# S1C31D01 register map
Vendor: Epson; Series: S1C31D01; File version: 1.00
CPU: CM0PLUS r0p1, little endian, MPU, no FPU, VTOR, 2 interrupt priority bits
Registers are 16-bit, read-write, reset 0x0 unless marked. A register's access mark holds for its fields unless they carry their own. Offsets are from the block's base; [hi:lo] are bit positions.

## MDC — Memory display controller
Base 0x40003000
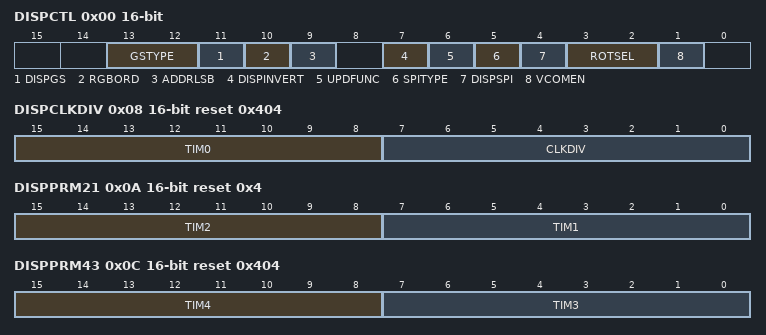
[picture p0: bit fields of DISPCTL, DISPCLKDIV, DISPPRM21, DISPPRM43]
0x00 DISPCTL — Display Control Register
  [13:12] GSTYPE — Select grayscale panel type
  [11] DISPGS — Select grayscale panel mode
  [10] RGBORD — This bit configures the order of the pixel data bits sent (LSB or MSB first) for Sharp panels.
    0=RGB (R is sent first); 1=BGR (G is sent first)
  [9] ADDRLSB — This bit configures the order of the Address bits sent (LSB or MSB first) for Sharp panels.
    0=MSB (MSB first); 1=LSB (LSB first)
  [7] DISPINVERT — This bit enables/disables inversion of pixels sent to the display.
    0=NORMAL (Normal (no inversion)); 1=INVERT (Pixel bits inverted)
  [6] UPDFUNC — This bit selects the function for Sharp or Epson display when frame update is triggered.
  [5] SPITYPE — This bit selects the type of Sharp panel.
  [4] DISPSPI — This bit selects the type of panel.
  [3:2] ROTSEL — This bit selects the rotation of the image from display RAM to the panel during a frame update.
    0=NOROT (No rotation (0 degrees)); 3=R270 (270-degree counterclockwise rotation); 2=R180 (180-degree counterclockwise rotation); 1=R90 (90-degree counterclockwise rotation)
  [1] VCOMEN — This bit enables or disables the VCOM and XFRP outputs. When enabled, the frequency of the VCOM /XFRP is determined by the MDC_DISPVCOMDIV register.
0x02 DISPWIDTH reset 0xB4 — Display Width Register
  [9:0] DISPWIDTH — Display width in pixels.
0x04 DISPHEIGHT reset 0xB4 — Display Height Register
  [9:0] DISPHEIGHT — Display height in pixels.
0x06 DISPVCOMDIV reset 0x222 — Display VCOM Clock Divider Register
  [15:0] DISPVCOMDIV — VCOM clock divider. VCOM/XFRP toggle period = [M*4*(VCOMCLKDIV + 1)],where M is the 32.768kHz clock period (1/32768).
0x08 DISPCLKDIV reset 0x404 — Display Clock Divider Register
  [15:8] TIM0
  [7:0] CLKDIV — Timing Parameter 0
0x0A DISPPRM21 reset 0x4 — Display Parameters 1 and 2 Register
  [15:8] TIM2 — Timing Parameter 2.
  [7:0] TIM1 — Timing Parameter 1.
0x0C DISPPRM43 reset 0x404 — Display Parameters 3 and 4 Register
  [15:8] TIM4 — Timing Parameter 4.
  [7:0] TIM3 — Timing Parameter 3.
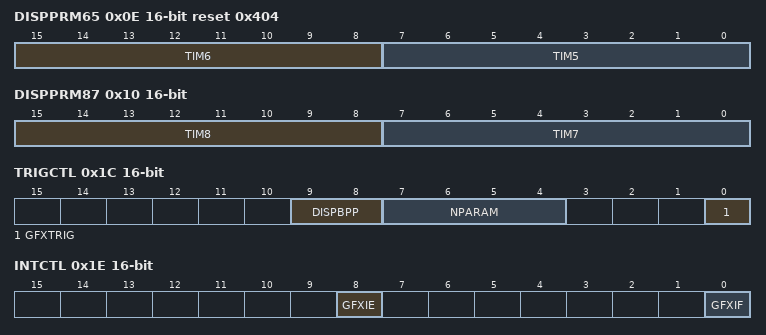
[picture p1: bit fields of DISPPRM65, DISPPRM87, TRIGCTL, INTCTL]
0x0E DISPPRM65 reset 0x404 — Display Parameters 5 and 6 Register
  [15:8] TIM6 — Timing Parameter 6.
  [7:0] TIM5 — Timing Parameter 5.
0x10 DISPPRM87 — Display Parameters 5 and 6 Register
  [15:8] TIM8 — Timing Parameter 8.
  [7:0] TIM7 — Timing Parameter 7.
0x12 DISPSTARTY — Display Update Start Line Register
  [9:0] STARTY — Starting line of image for display update
0x14 DISPENDY reset 0xB3 — Display Update End Line Register
  [9:0] ENDY — Ending line of image for display update.
0x16 DISPSTRIDE reset 0xB4 — MDC Display Frame Buffer Stride Register
  [9:0] DISPSTRIDE
0x18 DISPFRMBUF0 — Display Frame Buffer Base Address Register 0
  [15:0] FRMBUFFADDR — Bits 15-0 of the display frame buffer base address register.
0x1A DISPFRMBUF1 — Display Frame Buffer Base Address Register 1
  [15:0] FRMBUFFADDR — Bits 23-16 of the display frame buffer base address register.
0x1C TRIGCTL — Trigger Control Register
  [9:8] DISPBPP
  [7:4] NPARAM
  [0] GFXTRIG — This bit triggers the selected graphics acceleration function specified in GFXFUNC[2:0].
0x1E INTCTL — Interrupt Control Register
  [8] GFXIE — This bit enables/disables the graphics acceleration interrupt.
  [0] GFXIF — This bit is the graphics interrupt status flag.
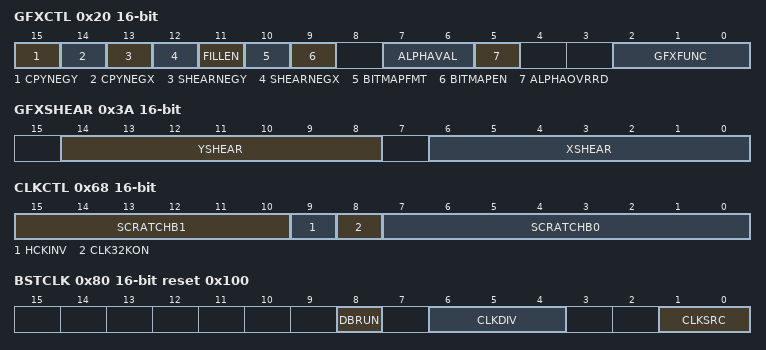
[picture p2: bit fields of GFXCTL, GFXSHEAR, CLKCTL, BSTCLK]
0x20 GFXCTL — Graphics Control Register
  [15] CPYNEGY — For the Copy functions, this bit selects whether or not the Y coordinate value of the input pixel should be negated (make negative) to create the effect of "flip around the X axis".
  [14] CPYNEGX — For the Copy functions, this bit selects whether or not the X coordinate value of the input pixel should be negated (make negative) to create the effect of "flip around the Y axis".
  [13] SHEARNEGY — For the Copy with shearing function, this bit selects whether or not the vertical shear value is negated (made negative).
  [12] SHEARNEGX — For the Copy with shearing function, this bit selects whether or not the horizontal shear value is negated (made negative).
  [11] FILLEN — This bit enables/disables fill option for drawing and copying functions.
  [10] BITMAPFMT — This bit selects 1-bit or 2-bit bitmap format for copying functions. See Section 0 for details.
  [9] BITMAPEN — This bit specifies whether the source for copying functions is an image or a bitmap.
  [7:6] ALPHAVAL — When alpha value override is enabled (ALPHAOVRRD=1), this specifies the override alpha value to use.
  [5] ALPHAOVRRD — This bit enables/disables alpha value override for copying functions.
  [2:0] GFXFUNC — These bits specify the graphics accelerator function to execute when the GFXTRIG bit in the MDC_TRIGCTL register is set to 1.
    0=CPOYROTSCALE (Image/bitmap copy with rotate and scale.); 1=COPYHVSHEAR (Image/bitmap copy with horizontal and vertical shear); 2=RECTDRAW (Rectangle (filled or unfilled) draw); 3=LINEDRAW (Line draw with thickness); 4=ELLIPDRAW (Ellipse (filled or unfilled) draw); 6=DISP_UPDATE (Display update); 7=ARCDRAW
0x22 GFXIXCENTER — Graphics Input X Center Register
  [9:0] IXCENTER — This register specifies different functions depending on the graphics function selected.
0x24 GFXIYCENTER — Graphics Input Y Center Register
  [9:0] IYCENTER — This register specifies different functions depending on the graphics function selected.
0x26 GFXIWIDTH — Graphics Input Width Register
  [9:0] IWIDTH — This register specifies different functions depending on the graphics function selected.
0x28 GFXIHEIGHT — Graphics Input Height Register
  [9:0] IHEIGHT — This register specifies different functions depending on the graphics function selected.
0x2A GFXOXCENTER — Graphics Output X Center Register
  [9:0] OXCENTER — This register specifies different functions depending on the graphics function selected.
0x2C GFXOYCENTER — Graphics Output Y Center Register
  [9:0] OYCENTER — This register specifies different functions depending on the graphics function selected.
0x2E GFXOWIDTH — Graphics Output Width Register
  [9:0] OWIDTH — This register specifies different functions depending on the graphics function selected.
0x30 GFXOHEIGHT — Graphics Output Height Register
  [9:0] OHEIGHT — This register specifies different functions depending on the graphics function selected.
0x32 GFXXLSCALE — Graphics X Left Scale Register
  [13:0] XLSCALE — This register is used by the COPYROTSCALE function to specify the scaling factor to be applied to the left half of the source/input image when copying to the destination/output image.
0x34 GFXXRSCALE — Graphics X Right Scale Register
  [13:0] XRSCALE — This register is used by the COPYROTSCALE function to specify the scaling factor to be applied to the right half of the source/input image when copying to the destination/output image.
0x36 GFXYTSCALE — Graphics Y Top Scale Register
  [13:0] YTSCALE — This register is used by the COPYROTSCALE function (image/bitmap copy with scale and rotation) to specify the scaling factor to be applied to the top half of the source/input image when copying to the destination/output image.
0x38 GFXYBSCALE — Graphics Y Bottom Scale Register
  [13:0] YBSCALE — This register is used by the COPYROTSCALE function to specify the scaling factor to be applied to the bottom half of the source/input image when copying to the destination/output image.
0x3A GFXSHEAR — Graphics X/Y Shear Register
  [14:8] YSHEAR — This register is used by the COPYHVSHEAR function to specify the vertical shearing factor to be applied to the source/input image when copying to the destination/output image.
  [6:0] XSHEAR — This register is used by the COPYHVSHEAR function to specify the horizontal shearing factor to be applied to the source/input image when copying to the destination/output image.
0x3C GFXROTVAL — Graphics Rotation Register
  [8:0] ROTVAL — This register is used by the COPYROTSCALE function to specify the angle of rotation of the source/input image when copying to the destination/output image. It is also used by the ARCDRAW function to specify the starting angle (from 0 degrees = positive x-axis).
0x3E GFXCOLOR reset 0x3 — Graphics Bitmap Color Register
  [7:0] COLOR
0x40 GFXIBADDR0 — Graphics Input (Source) Image Base Address Register 0
  [15:0] IBASEADDR — MDC Source Window Base Address Register
0x42 GFXIBADDR1 — Graphics Input (Source) Image Base Address Register 1
  [15:0] IBASEADDR — MDC Source Window Base Address Register
0x44 GFXOBADDR0 — Graphics Output (Destination) Image Base Address Register 0
  [15:0] OBASEADDR — MDC Destination Window Base Address Register
0x46 GFXOBADDR1 — Graphics Output (Destination) Image Base Address Register 1
  [15:0] OBASEADDR — MDC Destination Window Base Address Register
0x48 GFXISTRIDE — Graphics Input (Source) Image Stride Register
  [9:0] ISTRIDE
0x4A GFXOSTRIDE — Graphics Output (Destination) Image Stride Register
  [9:0] OSTRIDE
0x4C GFXOWLEFT — Output Window Left Edge Register
  [9:0] OWLEFT ro
0x4E GFXOWRIGHT — Output Window Right Edge Register
  [9:0] OWRIGHT ro
0x50 GFXOWTOP — Output Window Top Edge Register
  [9:0] OWTOP ro
0x52 GFXOWBOT — Output Window Bottom Edge Register
  [9:0] OWBOT ro
0x60 SCRATCHA0 — MDC Scratchpad A Register 0
  [15:0] SCRATCHA — MDC Scratchpad A Register
0x62 SCRATCHA1 — MDC Scratchpad A Register 1
  [15:0] SCRATCHA — MDC Scratchpad A Register
0x68 CLKCTL — MDC Clock Control Register
  [15:10] SCRATCHB1
  [9] HCKINV — HCLK invert
  [8] CLK32KON — Enable 32KHz clock
  [7:0] SCRATCHB0
0x80 BSTCLK reset 0x100 — Voltage Booster Clock Control Register
  [8] DBRUN, [6:4] CLKDIV, [1:0] CLKSRC
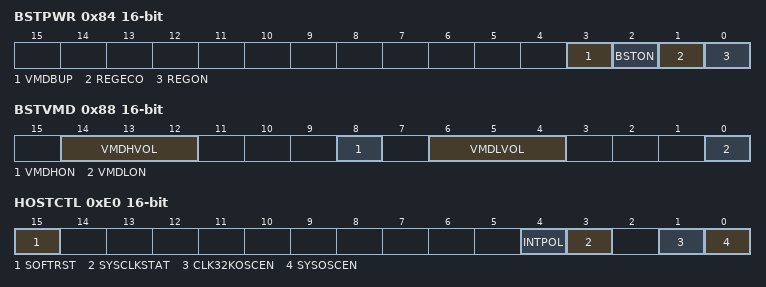
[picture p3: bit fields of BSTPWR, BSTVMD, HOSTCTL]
0x84 BSTPWR — Voltage Booster Power Control Register
  [3] VMDBUP, [2] BSTON, [1] REGECO, [0] REGON
0x88 BSTVMD — Voltage Booster VMD Output Control Register
  [14:12] VMDHVOL, [8] VMDHON, [6:4] VMDLVOL, [0] VMDLON
0xE0 HOSTCTL — MDC Host Control Register
  [15] SOFTRST — Soft reset
  [4] INTPOL
  [3] SYSCLKSTAT
  [1] CLK32KOSCEN
  [0] SYSOSCEN
